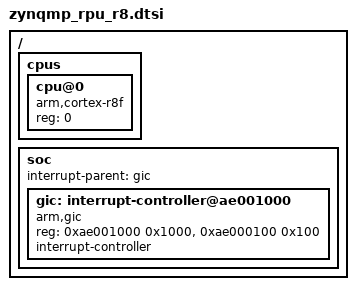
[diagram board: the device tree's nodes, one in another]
/*
 * Copyright (c) 2019 Stephanos Ioannidis <root@stephanos.io>
 *
 * SPDX-License-Identifier: Apache-2.0
 */

#include <arm/xilinx/zynqmp.dtsi>

/ {
	cpus {
		#address-cells = <1>;
		#size-cells = <0>;

		cpu@0 {
			device_type = "cpu";
			compatible = "arm,cortex-r8f";
			reg = <0>;
		};
	};

	soc {
		interrupt-parent = <&gic>;

		gic: interrupt-controller@ae001000 {
			compatible = "arm,gic";
			reg = <0xae001000 0x1000>,
					<0xae000100 0x100>;
			interrupt-controller;
			#interrupt-cells = <4>;
			status = "okay";
		};
	};
};
